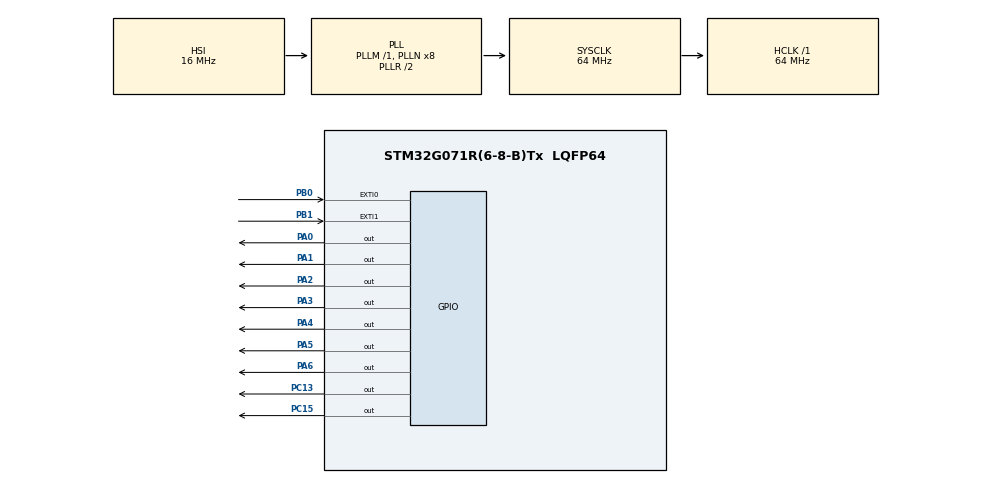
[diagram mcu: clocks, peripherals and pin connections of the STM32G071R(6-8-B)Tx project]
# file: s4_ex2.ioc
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Mcu.Family=STM32G0
Mcu.Name=STM32G071R(6-8-B)Tx
Mcu.Package=LQFP64
NVIC.EXTI0_1_IRQn=true\:0\:0\:false\:false\:true\:true\:true
PA0.Signal=GPIO_Output
PA1.Signal=GPIO_Output
PA2.Signal=GPIO_Output
PA3.Signal=GPIO_Output
PA4.Signal=GPIO_Output
PA5.Signal=GPIO_Output
PA6.Signal=GPIO_Output
PB0.GPIO_ModeDefaultEXTI=GPIO_MODE_IT_FALLING
PB0.GPIO_PuPd=GPIO_PULLUP
PB0.Signal=GPXTI0
PB1.GPIO_ModeDefaultEXTI=GPIO_MODE_IT_FALLING
PB1.GPIO_PuPd=GPIO_PULLUP
PB1.Signal=GPXTI1
PC13.Signal=GPIO_Output
PC15-OSC32_OUT\ (PC15).Signal=GPIO_Output
ProjectManager.HeapSize=0x200
ProjectManager.StackSize=0x400
ProjectManager.TargetToolchain=STM32CubeIDE
RCC.ADCFreq_Value=64000000
RCC.AHBFreq_Value=64000000
RCC.CortexFreq_Value=64000000
RCC.EXTERNAL_CLOCK_VALUE=48000
RCC.HCLKFreq_Value=64000000
RCC.HSE_VALUE=8000000
RCC.HSI_VALUE=16000000
RCC.LSE_VALUE=32768
RCC.SYSCLKFreq_VALUE=64000000
RCC.SYSCLKSource=RCC_SYSCLKSOURCE_PLLCLK
RCC.VCOOutputFreq_Value=128000000
VP_SYS_VS_DBSignals.Mode=DisableDeadBatterySignals
board=custom

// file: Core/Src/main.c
/* USER CODE BEGIN Header */
/**
  ******************************************************************************
  * @file           : main.c
  * @brief          : Main program body
  ******************************************************************************
  * @attention
  *
  * <h2><center>&copy; Copyright (c) 2022 STMicroelectronics.
  * All rights reserved.</center></h2>
  *
  * This software component is licensed by ST under BSD 3-Clause license,
  * the "License"; You may not use this file except in compliance with the
  * License. You may obtain a copy of the License at:
  *                        opensource.org/licenses/BSD-3-Clause
  *
  ******************************************************************************
  */
/* USER CODE END Header */
#include "main.h"
void SystemClock_Config(void);
static void MX_GPIO_Init(void);
int8_t i=0;
void HAL_GPIO_EXTI_Callback(uint16_t GPIO_Pin)
{
    if(GPIO_Pin ==GPIO_PIN_0)
    {
    	  i++;
    	  if(i==100)
    	   i=99;
    }
    else  if(GPIO_Pin ==GPIO_PIN_1)
       {
    	if(i>0)
    	  i--;
       }
 }

int main(void)
{
    HAL_Init();
   SystemClock_Config();
   MX_GPIO_Init();
  /* USER CODE BEGIN WHILE */
   unsigned char decode[10]= {0x3f,0x06,0x5B,0x4f,0x66,0x6d,      0x7d,0x07,0x7f,0x6f};
   unsigned char a,b;
  while (1)
  {
	  a=i%10;
	  HAL_GPIO_WritePin(GPIOC, GPIO_PIN_13, GPIO_PIN_SET);
	  HAL_GPIO_WritePin(GPIOC, GPIO_PIN_15, GPIO_PIN_RESET);
	  GPIOA->ODR = decode[a]; //Displaying ones
	  HAL_Delay(1);
	  b=i/10;
	  HAL_GPIO_WritePin(GPIOC, GPIO_PIN_13, GPIO_PIN_RESET);
	  HAL_GPIO_WritePin(GPIOC, GPIO_PIN_15, GPIO_PIN_SET);
	  GPIOA->ODR = decode[b]; //Displaying tens
	  HAL_Delay(1);
  }

  /* USER CODE END WHILE */
}

void SystemClock_Config(void)
{
  RCC_OscInitTypeDef RCC_OscInitStruct = {0};
  RCC_ClkInitTypeDef RCC_ClkInitStruct = {0};

  /** Configure the main internal regulator output voltage
  */
  HAL_PWREx_ControlVoltageScaling(PWR_REGULATOR_VOLTAGE_SCALE1);
  /** Initializes the RCC Oscillators according to the specified parameters
  * in the RCC_OscInitTypeDef structure.
  */
  RCC_OscInitStruct.OscillatorType = RCC_OSCILLATORTYPE_HSI;
  RCC_OscInitStruct.HSIState = RCC_HSI_ON;
  RCC_OscInitStruct.HSIDiv = RCC_HSI_DIV1;
  RCC_OscInitStruct.HSICalibrationValue = RCC_HSICALIBRATION_DEFAULT;
  RCC_OscInitStruct.PLL.PLLState = RCC_PLL_ON;
  RCC_OscInitStruct.PLL.PLLSource = RCC_PLLSOURCE_HSI;
  RCC_OscInitStruct.PLL.PLLM = RCC_PLLM_DIV1;
  RCC_OscInitStruct.PLL.PLLN = 8;
  RCC_OscInitStruct.PLL.PLLP = RCC_PLLP_DIV2;
  RCC_OscInitStruct.PLL.PLLQ = RCC_PLLQ_DIV2;
  RCC_OscInitStruct.PLL.PLLR = RCC_PLLR_DIV2;
  if (HAL_RCC_OscConfig(&RCC_OscInitStruct) != HAL_OK)
  {
    Error_Handler();
  }
  /** Initializes the CPU, AHB and APB buses clocks
  */
  RCC_ClkInitStruct.ClockType = RCC_CLOCKTYPE_HCLK|RCC_CLOCKTYPE_SYSCLK
                              |RCC_CLOCKTYPE_PCLK1;
  RCC_ClkInitStruct.SYSCLKSource = RCC_SYSCLKSOURCE_PLLCLK;
  RCC_ClkInitStruct.AHBCLKDivider = RCC_SYSCLK_DIV1;
  RCC_ClkInitStruct.APB1CLKDivider = RCC_HCLK_DIV1;

  if (HAL_RCC_ClockConfig(&RCC_ClkInitStruct, FLASH_LATENCY_2) != HAL_OK)
  {
    Error_Handler();
  }
}

static void MX_GPIO_Init(void)
{
  GPIO_InitTypeDef GPIO_InitStruct = {0};

  /* GPIO Ports Clock Enable */
  __HAL_RCC_GPIOC_CLK_ENABLE();
  __HAL_RCC_GPIOA_CLK_ENABLE();
  __HAL_RCC_GPIOB_CLK_ENABLE();

  /*Configure GPIO pin Output Level */
  HAL_GPIO_WritePin(GPIOC, GPIO_PIN_13|GPIO_PIN_15, GPIO_PIN_RESET);

  /*Configure GPIO pin Output Level */
  HAL_GPIO_WritePin(GPIOA, GPIO_PIN_0|GPIO_PIN_1|GPIO_PIN_2|GPIO_PIN_3
                          |GPIO_PIN_4|GPIO_PIN_5|GPIO_PIN_6, GPIO_PIN_RESET);

  /*Configure GPIO pins : PC13 PC15 */
  GPIO_InitStruct.Pin = GPIO_PIN_13|GPIO_PIN_15;
  GPIO_InitStruct.Mode = GPIO_MODE_OUTPUT_PP;
  GPIO_InitStruct.Pull = GPIO_NOPULL;
  GPIO_InitStruct.Speed = GPIO_SPEED_FREQ_LOW;
  HAL_GPIO_Init(GPIOC, &GPIO_InitStruct);

  /*Configure GPIO pins : PA0 PA1 PA2 PA3
                           PA4 PA5 PA6 */
  GPIO_InitStruct.Pin = GPIO_PIN_0|GPIO_PIN_1|GPIO_PIN_2|GPIO_PIN_3
                          |GPIO_PIN_4|GPIO_PIN_5|GPIO_PIN_6;
  GPIO_InitStruct.Mode = GPIO_MODE_OUTPUT_PP;
  GPIO_InitStruct.Pull = GPIO_NOPULL;
  GPIO_InitStruct.Speed = GPIO_SPEED_FREQ_LOW;
  HAL_GPIO_Init(GPIOA, &GPIO_InitStruct);

  /*Configure GPIO pins : PB0 PB1 */
  GPIO_InitStruct.Pin = GPIO_PIN_0|GPIO_PIN_1;
  GPIO_InitStruct.Mode = GPIO_MODE_IT_FALLING;
  GPIO_InitStruct.Pull = GPIO_PULLUP;
  HAL_GPIO_Init(GPIOB, &GPIO_InitStruct);

  /* EXTI interrupt init*/
  HAL_NVIC_SetPriority(EXTI0_1_IRQn, 0, 0);
  HAL_NVIC_EnableIRQ(EXTI0_1_IRQn);

}

void Error_Handler(void)
{
  __disable_irq();
  while (1)
  {
  }
}

/************************ (C) COPYRIGHT STMicroelectronics *****END OF FILE****/
